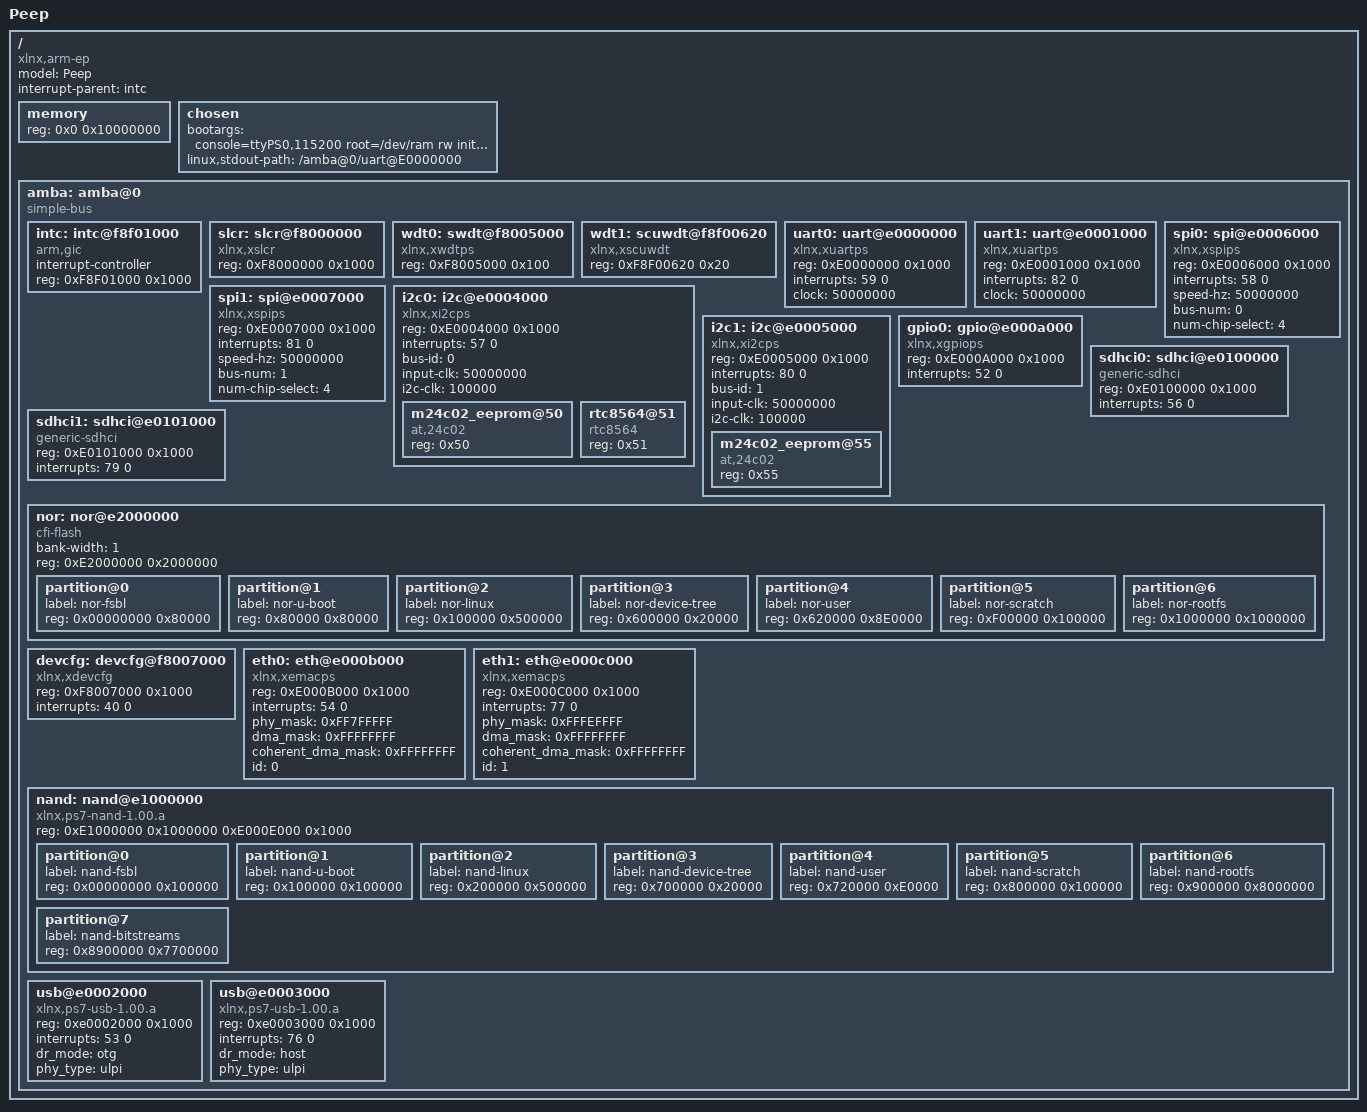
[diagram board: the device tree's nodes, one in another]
/dts-v1/;

/ {
	model = "Peep";
	compatible = "xlnx,arm-ep";
	#address-cells = <1>;
	#size-cells = <1>;
	interrupt-parent = <&intc>;

	memory {
		device_type = "memory";
		reg = <0x0 0x10000000>;
   	};

	chosen {
		bootargs = "console=ttyPS0,115200 root=/dev/ram rw initrd=0x800000,8M earlyprintk";
		linux,stdout-path = "/amba@0/uart@E0000000";
	};

	amba: amba@0 {
		compatible = "simple-bus";
		#address-cells = <1>;
		#size-cells = <1>;
		ranges;

		intc: intc@f8f01000 {
			interrupt-controller;
			compatible = "arm,gic";
			reg = <0xF8F01000 0x1000>;
			#interrupt-cells = <2>;
		};

		slcr: slcr@f8000000 {
			compatible = "xlnx,xslcr";
			reg = <0xF8000000 0x1000>;
		};

		wdt0: swdt@f8005000 {
			device_type = "watchdog";
			compatible = "xlnx,xwdtps";
			reg = <0xF8005000 0x100>;
		};

		wdt1: scuwdt@f8f00620 {
			device_type = "watchdog";
			compatible = "xlnx,xscuwdt";
			reg = <0xF8F00620 0x20>;
		};
	
		uart0: uart@e0000000 {
			compatible = "xlnx,xuartps";
			reg = <0xE0000000 0x1000>;
			interrupts = <59 0>;
			clock = <50000000>;
		};
	
		uart1: uart@e0001000 {
			compatible = "xlnx,xuartps";
			reg = <0xE0001000 0x1000>;
			interrupts = <82 0>;
			clock = <50000000>;
		};
	
		spi0: spi@e0006000 {
			compatible = "xlnx,xspips";
			reg = <0xE0006000 0x1000>;
			interrupts = <58 0>;
			speed-hz = <50000000>;
			bus-num = <0>;
			num-chip-select = <4>;
		};

		spi1: spi@e0007000 {
			compatible = "xlnx,xspips";
			reg = <0xE0007000 0x1000>;
			interrupts = <81 0>;
			speed-hz = <50000000>;
			bus-num = <1>;
			num-chip-select = <4>;
		};

		i2c0: i2c@e0004000 {
			compatible = "xlnx,xi2cps";
			reg = <0xE0004000 0x1000>;
			interrupts = <57 0>;
			bus-id = <0>;
			input-clk = <50000000>;
			i2c-clk = <100000>;
			
			#address-cells = <1>;
			#size-cells = <0>;
			m24c02_eeprom@50 {
				compatible = "at,24c02";
				reg = <0x50>;
			};

			rtc8564@51 {
				compatible = "rtc8564";
				reg = <0x51>;
			};
		};

		i2c1: i2c@e0005000 {
			compatible = "xlnx,xi2cps";
			reg = <0xE0005000 0x1000>;
			interrupts = <80 0>;
			bus-id = <1>;
			input-clk = <50000000>;
			i2c-clk = <100000>;

			#address-cells = <1>;
			#size-cells = <0>;
			m24c02_eeprom@55 {
				compatible = "at,24c02";
				reg = <0x55>;
			};
		};

		gpio0: gpio@e000a000 {
			compatible = "xlnx,xgpiops";
			reg = <0xE000A000 0x1000>;
			interrupts = <52 0>;
		};

		sdhci0: sdhci@e0100000 {
			compatible = "generic-sdhci";
			reg = <0xE0100000 0x1000>;
			interrupts = <56 0>;
		};

		sdhci1: sdhci@e0101000 {
			compatible = "generic-sdhci";
			reg = <0xE0101000 0x1000>;
			interrupts = <79 0>;
		};

		nor: nor@e2000000 {
			compatible = "cfi-flash";
			bank-width = <1>;
			reg = <0xE2000000 0x2000000>;		/* 32MB */
			#address-cells = <1>;
			#size-cells = <1>;
			partition@0 {
				label = "nor-fsbl";
				reg = <0x00000000 0x80000>;	/* 512K */
			};
			partition@1 {
				label = "nor-u-boot";
				reg = <0x80000 0x80000>;	/* 512K */
			};
			partition@2 {
				label = "nor-linux";
				reg = <0x100000 0x500000>;	/* 5 MB */
			};
			partition@3 {
				label = "nor-device-tree";
				reg = <0x600000 0x20000>;	/* 128K */
			};
			partition@4{
				label = "nor-user";
				reg = <0x620000 0x8E0000>;	/* 8875K */
			};
			partition@5{
				label = "nor-scratch";
				reg = <0xF00000 0x100000>;	/* 1 MB */
			};
			partition@6{
				label = "nor-rootfs";
				reg = <0x1000000 0x1000000>;	/* 16 MB */
			};
                };

		devcfg: devcfg@f8007000 {
			compatible = "xlnx,xdevcfg";
			reg = <0xF8007000 0x1000>;
			interrupts = <40 0>;
		};
		eth0: eth@e000b000 {
			compatible = "xlnx,xemacps";
			reg = <0xE000B000 0x1000>;
			interrupts = <54 0>;
			phy_mask = <0xFF7FFFFF>;
			dma_mask = <0xFFFFFFFF>;
			coherent_dma_mask=<0xFFFFFFFF>;
			id = <0>;
		};

		eth1: eth@e000c000 {
			compatible = "xlnx,xemacps";
			reg = <0xE000C000 0x1000>;
			interrupts = <77 0>;
			phy_mask = <0xFFFEFFFF>;
			dma_mask = <0xFFFFFFFF>;
			coherent_dma_mask=<0xFFFFFFFF>;
			id = <1>;
		};

		nand: nand@e1000000 {
			compatible = "xlnx,ps7-nand-1.00.a";
			reg = <0xE1000000 0x1000000 0xE000E000 0x1000>;
			#address-cells = <1>;
			#size-cells = <1>;
			partition@0 {
				label = "nand-fsbl";
				reg = <0x00000000 0x100000>;	/* 1 MB */
			};
			partition@1 {
				label = "nand-u-boot";
				reg = <0x100000 0x100000>;	/* 1 MB */
			};
			partition@2 {
				label = "nand-linux";
				reg = <0x200000 0x500000>;	/* 5 MB */
			};
			partition@3 {
				label = "nand-device-tree";
				reg = <0x700000 0x20000>;	/* 128 KB */
			};
			partition@4 {
				label = "nand-user";
				reg = <0x720000 0xE0000>;	/* 896 KB */
			};
			partition@5 {
				label = "nand-scratch";
				reg = <0x800000 0x100000>;	/* 1 MB */
			};
			partition@6 {
				label = "nand-rootfs";
				reg = <0x900000 0x8000000>;	/* 128 MB */
			};
			partition@7 {
				label = "nand-bitstreams";
				reg = <0x8900000 0x7700000>;	/* 119 MB */
			};
		};

		usb@e0002000 {
			compatible = "xlnx,ps7-usb-1.00.a";
			reg = <0xe0002000 0x1000>;
			interrupts = <53 0>;
			dr_mode = "otg";
			phy_type = "ulpi";
		};

		usb@e0003000 {
			compatible = "xlnx,ps7-usb-1.00.a";
			reg = <0xe0003000 0x1000>;
			interrupts = <76 0>;
			dr_mode = "host";
			phy_type = "ulpi";
		};
	};
};
